AUTOSAR XML (schema 3.1.2)
standard types defined: SInt8, UInt8, UInt16, UInt32, Boolean
package /System
  ecu instance CEM: com-processing-period=0.005
    can communication controller CEMController
    communication connector ComConnector: channel=Channel, comm-controller=CEMController
  ecu instance REM: com-processing-period=0.005
    can communication controller REMController
    communication connector ComConnector: channel=Channel, comm-controller=REMController
  system TargetSystem: fibex-element=[CEM, CanCluster, IDPU_BRAKE, IDPU_BRAKE, SIG_BRAKE_IDPU_BRAKE, IPDU_LEFT_RIGHT, IPDU_LEFT_RIGHT, SIG_LEFT_IPDU_LEFT_RIGHT, SIG_RIGHT_IPDU_LEFT_RIGHT]
    mapping MAPPING
      sw-mappings:
        swc to ecu mapping a88e37d21c78744b19b30be8be6fa7d: ecu-instance=CEM
          component:
            BodyDemoArchitecture.IoHwAb_CEM.ADC2Voltage
            BodyDemoArchitecture.BrakePedalSensor
            BodyDemoArchitecture.WarnLightsSensor
            BodyDemoArchitecture.IoHwAb_CEM.IoHwAbCEMDioComponent
            BodyDemoArchitecture.Indicator.IndicatorAtomic
            BodyDemoArchitecture.PedalToLamp
            BodyDemoArchitecture.TurnSwitchSensor
            BodyDemoArchitecture.CalprmComponent
        swc to ecu mapping ab7ad628e75594871bc1c9ff9870552: ecu-instance=REM
          component:
            BodyDemoArchitecture.RearLeftActuator
            BodyDemoArchitecture.IoHwAb_REM.IoHwAbREMDioComponent
            BodyDemoArchitecture.BrakeLampActuator
            BodyDemoArchitecture.IoHwAb_REM.Percentage2DIO
            BodyDemoArchitecture.RearRightActuator
    software composition BodyDemoArchitecture: software-composition=BodyDemoArchitecture
package /System/Cluster
  can cluster CanCluster: speed=0
    physical channel Channel
      frame IDPU_BRAKE: id 0x101, from CEM, to REM, frame-length=4, can-addressing-mode=STANDARD
        carries pdu IDPU_BRAKE: packing-byte-order=big-endian, start-position=7
        pdu IDPU_BRAKE: length=32, cyclic-timing={repeating-time=0.1, starting-time=0}, minimum-delay=0.02
          signal SIG_BRAKE_IDPU_BRAKE: start 7, 32 bit, big-endian, data-type=UInt32, to REM
      frame IPDU_LEFT_RIGHT: id 0x100, from CEM, to REM, frame-length=2, can-addressing-mode=STANDARD
        carries pdu IPDU_LEFT_RIGHT: packing-byte-order=big-endian, start-position=7
        pdu IPDU_LEFT_RIGHT: length=16, cyclic-timing={repeating-time=0.1, starting-time=0}, minimum-delay=0.02
          signal SIG_LEFT_IPDU_LEFT_RIGHT: start 7, 8 bit, big-endian, data-type=SInt8, to REM
          signal SIG_RIGHT_IPDU_LEFT_RIGHT: start 15, 8 bit, big-endian, data-type=SInt8, to REM
package /Application
  composition type BodyDemoArchitecture
    11 x component:
      Indicator: type=Indicator
      IoHwAb_CEM: type=IoHwAb_CEM
      IoHwAb_REM: type=IoHwAb_REM
      TurnSwitchSensor: type=TurnSwitchSensor
      WarnLightsSensor: type=WarnLightsSensor
      RearLeftActuator: type=RearLeftActuator
      RearRightActuator: type=RearRightActuator
      BrakePedalSensor: type=BrakePedalSensor
      PedalToLamp: type=PedalToLamp
      BrakeLampActuator: type=BrakeLampActuator
      CalprmComponent: type=CalprmComponent
    connect Indicator.right -> RearRightActuator.signal
    connect Indicator.left -> RearLeftActuator.signal
    connect IoHwAb_CEM.wls -> WarnLightsSensor.io
    connect IoHwAb_REM.rightIndicatorBulb -> RearRightActuator.io
    connect IoHwAb_CEM.tss_right -> TurnSwitchSensor.right
    connect IoHwAb_REM.leftBrakeLamp -> BrakeLampActuator.io_left
    connect IoHwAb_REM.rightBrakeLamp -> BrakeLampActuator.io_right
    connect PedalToLamp.lamp -> BrakeLampActuator.signal
    connect TurnSwitchSensor.out -> Indicator.tss
    connect IoHwAb_CEM.tss_left -> TurnSwitchSensor.left
    connect WarnLightsSensor.out -> Indicator.wls
    connect IoHwAb_REM.leftIndicatorBulb -> RearLeftActuator.io
    connect BrakePedalSensor.pedal -> PedalToLamp.pedal
    connect IoHwAb_CEM.pedal -> BrakePedalSensor.io
  composition type Indicator
    require port tss: unqueued-receiver-com-spec{data-element=if_tss/value, init-value=aa75e85b0e48d493f9208f4aeb0a607, resync-time=0}, required-interface=if_tss
    require port wls: queued-receiver-com-spec{data-element=event, queue-length=1}, required-interface=if_wls
    provide port left: unqueued-sender-com-spec=LEFT, provided-interface=if_bulb_left
    provide port right: unqueued-sender-com-spec=RIGHT, provided-interface=if_bulb_right
    component IndicatorAtomic: type=IndicatorAtomic
    delegate IndicatorAtomic.wls <-> outer port Indicator/wls
    delegate IndicatorAtomic.tss <-> outer port Indicator/tss
    delegate IndicatorAtomic.left <-> outer port Indicator/left
    delegate IndicatorAtomic.right <-> outer port Indicator/right
  sender receiver interface if_tss
    data value: type=dt_tss
  integer type dt_tss: lower-limit=-128, upper-limit=127
  sender receiver interface if_wls
    data event: type=dt_wls, is-queued=true
  integer type dt_wls: lower-limit=0, upper-limit=255
  sender receiver interface if_bulb_left
    data LEFT: type=dt_bulb
  sender receiver interface if_bulb_right
    data RIGHT: type=dt_bulb
  integer type dt_bulb: lower-limit=-128, upper-limit=127
  constant specification aa75e85b0e48d493f9208f4aeb0a607
    value:
      integer literal aa75e85b0e48d493f9208f4aeb0a607: type=dt_tss, value=0
  constant specification aeba547061bbc4f628a465c655b5dce
    value:
      integer literal aeba547061bbc4f628a465c655b5dce: type=dt_bulb, value=0
  constant specification a6086f2506f88401497b997b97eebe1
    value:
      integer literal a6086f2506f88401497b997b97eebe1: type=dt_bulb, value=0
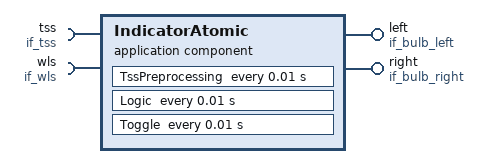
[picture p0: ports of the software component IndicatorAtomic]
  application software component type IndicatorAtomic
    require port tss: unqueued-receiver-com-spec{data-element=if_tss/value, init-value=aa75e85b0e48d493f9208f4aeb0a607, resync-time=0}, required-interface=if_tss
    require port wls: queued-receiver-com-spec{data-element=event, queue-length=1}, required-interface=if_wls
    provide port left: unqueued-sender-com-spec{data-element=LEFT, init-value=aeba547061bbc4f628a465c655b5dce}, provided-interface=if_bulb_left
    provide port right: unqueued-sender-com-spec{data-element=RIGHT, init-value=a6086f2506f88401497b997b97eebe1}, provided-interface=if_bulb_right
  internal behavior IB_IndicatorAtomic: component=IndicatorAtomic
    data received event WlsEventReceived: start-on-event=WlsPreprocessing, data=wls.event
    timing event TssCyclic10ms: start-on-event=TssPreprocessing, period=0.01
    timing event LogicCyclic10ms: start-on-event=Logic, period=0.01
    timing event ToggleCyclic10ms: start-on-event=Toggle, period=0.01
    exclusive area ea1
    exclusive area ea2
    8 x inter runnable variable:
      indicator_status: type=dt_is, communication-approach=IMPLICIT, init-value=a2aeeb626cf3e4245a92932e870d65f
      wls_status: type=dt_wls, communication-approach=IMPLICIT, init-value=a40037445f1c546d5ae7e79459c02b6
      tss_status: type=dt_tss, communication-approach=IMPLICIT, init-value=a7ba438111a914ed899a66eb1f9c4ee
      bool{0..4}: type=Boolean, communication-approach=EXPLICIT
    per-instance-calprms:
      calprm element prototype CalprmValue2: category=VALUE, sw-calibration-access=READ-WRITE, sw-record-layout=RL_UInt8, type=UInt8
    per instance memory PerInstanceMemory: type=myType, type-definition=uint32
    4 x runnable:
      TssPreprocessing: can-enter-exclusive-area=ea1, per-instance-calprm-access=IB_IndicatorAtomic/CalprmValue2, shared-calprm-access=IB_IndicatorAtomic/CalprmValue1, written-variable=[tss_status, bool0, bool1, bool2, bool3, bool4]
        data read access TssPreprocessing_DRA_1_ia: data-element=tss.value
      WlsPreprocessing: runs-inside-exclusive-area=ea2, written-variable=wls_status
        data receive point WlsPreprocessing_DRP_1_ia: data-element=wls.event
      Logic: read-variable=[tss_status, wls_status, bool0, bool1, bool2, bool3, bool4], written-variable=indicator_status
      Toggle: read-variable=indicator_status
        data write access Toggle_DWA_1_ia: data-element=left.LEFT
        data write access Toggle_DWA_2_ia: data-element=right.RIGHT
    service-needss:
      swc nv block needs SwcNvBlockNeed1: n-data-sets=1, readonly=true, reliability=HIGH, resistant-to-changed-sw=false, restore-at-start=true, write-only-once=false, writing-frequency=1, writing-priority=HIGH
      swc nv block needs SwcNvBlockNeed2: n-data-sets=1, readonly=false, reliability=LOW, resistant-to-changed-sw=false, restore-at-start=true, write-only-once=false, writing-frequency=1, writing-priority=LOW
    shared-calprms:
      calprm element prototype CalprmValue1: category=VALUE, sw-calibration-access=READ-WRITE, sw-record-layout=RL_UInt16, type=UInt16
  integer type dt_is: compu {1=LEFT_SIGNAL, 2=RIGHT_SIGNAL, 3=BOTH_SIGNAL, 0=false}, lower-limit=0, upper-limit=65535
  integer type AuxU16_dt_is: lower-limit=0, upper-limit=65535
  constant specification a2aeeb626cf3e4245a92932e870d65f
    value:
      integer literal a2aeeb626cf3e4245a92932e870d65f: type=dt_is, value=0
  constant specification a40037445f1c546d5ae7e79459c02b6
    value:
      integer literal a40037445f1c546d5ae7e79459c02b6: type=dt_wls, value=0
  constant specification a7ba438111a914ed899a66eb1f9c4ee
    value:
      integer literal a7ba438111a914ed899a66eb1f9c4ee: type=dt_tss, value=0
  swc implementation IMPL_IndicatorAtomic: behavior=IB_IndicatorAtomic
    code-descriptors:
      code IMPL_IndicatorAtomic: type=SRC
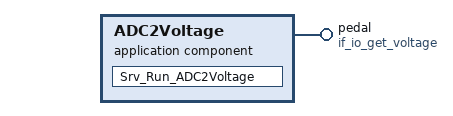
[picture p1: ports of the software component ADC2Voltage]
  application software component type ADC2Voltage
    provide port pedal: server-com-spec{operation=OP_GET, queue-length=1}, provided-interface=if_io_get_voltage
  internal behavior IB_ADC2Voltage: component=ADC2Voltage
    operation invoked event OpEv_OP_GET: start-on-event=Srv_Run_ADC2Voltage, operation=pedal.OP_GET
    runnable Srv_Run_ADC2Voltage: can-be-invoked-concurrently=true, symbol=ADC2Voltage
  swc implementation IMPL_ADC2Voltage: behavior=IB_ADC2Voltage
    code-descriptors:
      code IMPL_ADC2Voltage: type=SRC
  internal behavior IB_Percentage2DIO: component=Percentage2DIO
    4 x operation invoked event:
      OpEv_Left_OP_SET: start-on-event=Srv_Run_Left_OP_SET, operation=left.OP_SET
      OpEv_Left_OP_DIAG: start-on-event=Srv_Run_Left_OP_DIAG, operation=left.OP_DIAG
      OpEv_Right_OP_SET: start-on-event=Srv_Run_Right_OP_SET, operation=right.OP_SET
      OpEv_Right_OP_DIAG: start-on-event=Srv_Run_Right_OP_DIAG, operation=right.OP_DIAG
    4 x runnable, all with can-be-invoked-concurrently=true:
      Srv_Run_Left_OP_SET: symbol=Percentage2DIO_Left_OP_SET
        4 x sync call, all with timeout=0:
          leftNormal_OP_WC: operation=leftNormal.OP_WC
          leftFull_OP_WC: operation=leftFull.OP_WC
          leftNormal_OP_RC: operation=leftNormal.OP_RC
          leftFull_OP_RC: operation=leftFull.OP_RC
      Srv_Run_Right_OP_SET: symbol=Percentage2DIO_Right_OP_SET
        4 x sync call, all with timeout=0:
          rightFull_OP_WC: operation=rightFull.OP_WC
          rightNormal_OP_WC: operation=rightNormal.OP_WC
          rightFull_OP_RC: operation=rightFull.OP_RC
          rightNormal_OP_RC: operation=rightNormal.OP_RC
      Srv_Run_Left_OP_DIAG: symbol=Percentage2DIO_Left_OP_DIAG
      Srv_Run_Right_OP_DIAG: symbol=Percentage2DIO_Right_OP_DIAG
  swc implementation IMPL_Percentage2DIO: behavior=IB_Percentage2DIO
    code-descriptors:
      code IMPL_Percentage2DIO: type=SRC
  constant specification a51067134f9f24a9d9f2ec09784b782
    value:
      integer literal a51067134f9f24a9d9f2ec09784b782: type=dt_tss, value=0
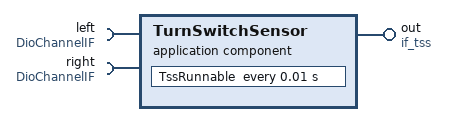
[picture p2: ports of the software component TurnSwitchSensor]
  application software component type TurnSwitchSensor
    provide port out: unqueued-sender-com-spec{data-element=if_tss/value, init-value=a51067134f9f24a9d9f2ec09784b782}, provided-interface=if_tss
    require port left: required-interface=DioChannelIF
    require port right: required-interface=DioChannelIF
  internal behavior IB_TurnSwitchSensor: component=TurnSwitchSensor
    timing event TimingEvent_10ms: start-on-event=TssRunnable, period=0.01
    runnable TssRunnable
      data write access DWA_out_value: data-element=out.value
      4 x sync call, all with timeout=0:
        left_OP_RC: operation=left.OP_RC
        left_OP_WC: operation=left.OP_WC
        right_OP_WC: operation=right.OP_WC
        right_OP_RC: operation=right.OP_RC
  swc implementation IMPL_TurnSwitchSensor: behavior=IB_TurnSwitchSensor
    code-descriptors:
      code IMPL_TurnSwitchSensor: type=SRC
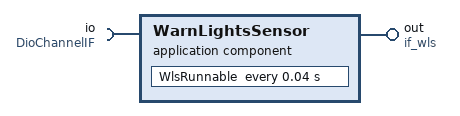
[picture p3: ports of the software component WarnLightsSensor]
  application software component type WarnLightsSensor
    provide port out: queued-sender-com-spec=event, provided-interface=if_wls
    require port io: required-interface=DioChannelIF
  internal behavior IB_WarnLightsSensor: component=WarnLightsSensor
    timing event TimingEvent_40ms: start-on-event=WlsRunnable, period=0.04
    runnable WlsRunnable
      data send point DSP_out_event: data-element=out.event
      sync call io_OP_RC: operation=io.OP_RC, timeout=0
      sync call io_OP_WC: operation=io.OP_WC, timeout=0
  swc implementation IMPL_WarnLightsSensor: behavior=IB_WarnLightsSensor
    code-descriptors:
      code IMPL_WarnLightsSensor: type=SRC
  constant specification a54a6a9694b41497d943bf20cd91112
    value:
      integer literal a54a6a9694b41497d943bf20cd91112: type=dt_bulb, value=0
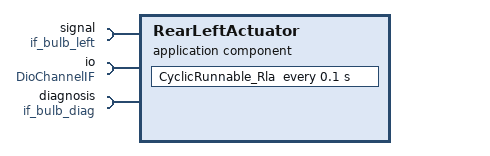
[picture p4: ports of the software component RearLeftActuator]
  application software component type RearLeftActuator
    require port signal: unqueued-receiver-com-spec{data-element=LEFT, init-value=a54a6a9694b41497d943bf20cd91112, resync-time=0}, required-interface=if_bulb_left
    require port io: required-interface=DioChannelIF
    require port diagnosis: required-interface=if_bulb_diag
  client server interface if_bulb_diag
    operation SetStatus
      arg status: type=dt_diag_status, direction=IN
  integer type dt_diag_status: compu {0=no_problem, 1=problem}, lower-limit=0, upper-limit=65535
  integer type AuxU16_dt_diag_status: lower-limit=0, upper-limit=65535
  internal behavior IB_RearLeftActuator: component=RearLeftActuator
    timing event Cyclic100ms: start-on-event=CyclicRunnable_Rla, period=0.1
    runnable CyclicRunnable_Rla
      data read access DRA_signal_value: data-element=signal.LEFT
      sync call diagnosis_SetStatus: operation=diagnosis.SetStatus, timeout=0
      sync call io_OP_WC: operation=io.OP_WC, timeout=0
      sync call io_OP_RC: operation=io.OP_RC, timeout=0
  swc implementation IMPL_FrontLeftActuator: behavior=IB_RearLeftActuator
    code-descriptors:
      code IMPL_FrontLeftActuator: type=SRC
  constant specification aead801ed2e734a3aa2dc432880381f
    value:
      integer literal aead801ed2e734a3aa2dc432880381f: type=dt_bulb, value=0
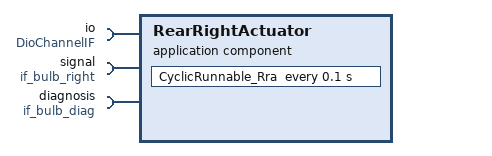
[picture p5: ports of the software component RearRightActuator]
  application software component type RearRightActuator
    require port io: required-interface=DioChannelIF
    require port signal: unqueued-receiver-com-spec{data-element=RIGHT, init-value=aead801ed2e734a3aa2dc432880381f, resync-time=0}, required-interface=if_bulb_right
    require port diagnosis: required-interface=if_bulb_diag
  internal behavior IB_RearRightActuator: component=RearRightActuator
    timing event Cyclic100ms: start-on-event=CyclicRunnable_Rra, period=0.1
    runnable CyclicRunnable_Rra
      data read access DRA_signal_value: data-element=signal.RIGHT
      sync call diagnosis_SetStatus: operation=diagnosis.SetStatus, timeout=0
      sync call io_OP_WC: operation=io.OP_WC, timeout=0
      sync call io_OP_RC: operation=io.OP_RC, timeout=0
  swc implementation IMPL_FrontRightActuator: behavior=IB_RearRightActuator
    code-descriptors:
      code IMPL_FrontRightActuator: type=SRC
  constant specification af237034bf74f4bf5920f44a10a4f76
    value:
      integer literal af237034bf74f4bf5920f44a10a4f76: type=dt_percentage, value=0
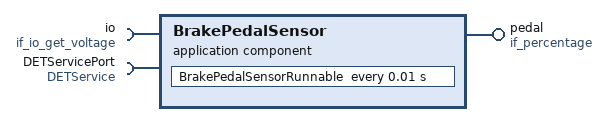
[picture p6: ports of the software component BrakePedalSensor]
  application software component type BrakePedalSensor
    provide port pedal: unqueued-sender-com-spec{data-element=if_percentage/value, init-value=af237034bf74f4bf5920f44a10a4f76}, provided-interface=if_percentage
    require port io: required-interface=if_io_get_voltage
    require port DETServicePort: required-interface=DETService
  sender receiver interface if_percentage
    data value: type=dt_percentage
  sender receiver interface if_brake
    data BRAKE: type=dt_percentage
  integer type dt_percentage: compu {}, lower-limit=0, upper-limit=4294967295
  integer type AuxU32_dt_percentage: lower-limit=0, upper-limit=4294967295
  internal behavior IB_BrakePedalSensor: component=BrakePedalSensor
    timing event Timing_10ms: start-on-event=BrakePedalSensorRunnable, period=0.01
    runnable BrakePedalSensorRunnable
      data write access DWA_pedal_value: data-element=pedal.value
      sync call io_OP_GET: operation=io.OP_GET, timeout=0
      sync call DETServicePort_ReportError: operation=DETServicePort.ReportError, timeout=0
  swc implementation IMPL_BrakePedalSensor: behavior=IB_BrakePedalSensor
    code-descriptors:
      code IMPL_BrakePedalSensor: type=SRC
  constant specification af536b2f1f3374592a77e6ba25805e6
    value:
      integer literal af536b2f1f3374592a77e6ba25805e6: type=dt_percentage, value=0
  constant specification a34ded2542c4b4ab7930b8ab2fa0993
    value:
      integer literal a34ded2542c4b4ab7930b8ab2fa0993: type=dt_percentage, value=0
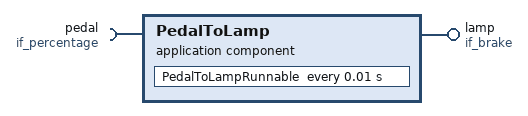
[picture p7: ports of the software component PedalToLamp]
  application software component type PedalToLamp
    require port pedal: unqueued-receiver-com-spec{data-element=if_percentage/value, init-value=af536b2f1f3374592a77e6ba25805e6, resync-time=0}, required-interface=if_percentage
    provide port lamp: unqueued-sender-com-spec{data-element=BRAKE, init-value=a34ded2542c4b4ab7930b8ab2fa0993}, provided-interface=if_brake
  internal behavior IB_PedalToLamp: component=PedalToLamp
    timing event Timing_10ms: start-on-event=PedalToLampRunnable, period=0.01
    runnable PedalToLampRunnable
      data read access DRA_pedal_value: data-element=pedal.value
      data write access DWA_lamp_value: data-element=lamp.BRAKE
  swc implementation IMPL_PedalToLamp: behavior=IB_PedalToLamp
    code-descriptors:
      code IMPL_PedalToLamp: type=SRC
  constant specification a674ab0de6f3d43caacb785465b088c
    value:
      integer literal a674ab0de6f3d43caacb785465b088c: type=dt_percentage, value=0
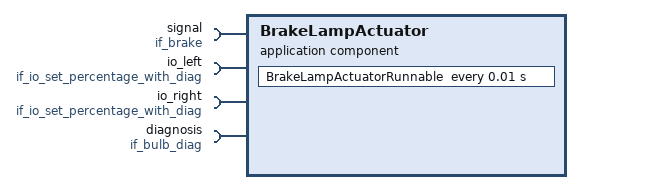
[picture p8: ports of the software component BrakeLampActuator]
  application software component type BrakeLampActuator
    4 x require port:
      signal: unqueued-receiver-com-spec{data-element=BRAKE, init-value=a674ab0de6f3d43caacb785465b088c, resync-time=0}, required-interface=if_brake
      io_left: required-interface=if_io_set_percentage_with_diag
      io_right: required-interface=if_io_set_percentage_with_diag
      diagnosis: required-interface=if_bulb_diag
  internal behavior IB_BrakeLampActuator: component=BrakeLampActuator
    timing event Timing_10ms: start-on-event=BrakeLampActuatorRunnable, period=0.01
    runnable BrakeLampActuatorRunnable
      data read access DRA_signal_value: data-element=signal.BRAKE
      5 x sync call, all with timeout=0:
        io_left_OP_SET: operation=io_left.OP_SET
        io_left_OP_DIAG: operation=io_left.OP_DIAG
        io_right_OP_SET: operation=io_right.OP_SET
        io_right_OP_DIAG: operation=io_right.OP_DIAG
        diagnosis_SetStatus: operation=diagnosis.SetStatus
  swc implementation IMPL_BrakeLampActuator: behavior=IB_BrakeLampActuator
    code-descriptors:
      code IMPL_BrakeLampActuator: type=SRC
  constant specification a44a60d3d162743dbae6e6dbb052677
    value:
      integer literal a44a60d3d162743dbae6e6dbb052677: type=dt_diag_status, value=0
  sender receiver interface if_diag_status
    data status: type=dt_diag_status
package /IoHwAbsPackage
  composition type IoHwAb_CEM
    4 x provide port:
      tss_left: provided-com-specs=[{operation=OP_WC, queue-length=1}, {operation=OP_RC, queue-length=1}], provided-interface=DioChannelIF
      tss_right: provided-com-specs=[{operation=OP_WC, queue-length=1}, {operation=OP_RC, queue-length=1}], provided-interface=DioChannelIF
      wls: provided-com-specs=[{operation=OP_WC, queue-length=1}, {operation=OP_RC, queue-length=1}], provided-interface=DioChannelIF
      pedal: server-com-spec{operation=OP_GET, queue-length=1}, provided-interface=if_io_get_voltage
    component ADC2Voltage: type=ADC2Voltage
    component IoHwAbCEMDioComponent: type=IoHwAbCEMDioComponent
    delegate ADC2Voltage.pedal <-> outer port IoHwAb_CEM/pedal
    delegate IoHwAbCEMDioComponent.S2_WARNLIGHT_SWITCH <-> outer port wls
    delegate IoHwAbCEMDioComponent.S1_TURN_SWITCH_RIGHT <-> outer port tss_right
    delegate IoHwAbCEMDioComponent.S4_TURN_SWITCH_LEFT <-> outer port tss_left
  composition type IoHwAb_REM
    4 x provide port:
      leftIndicatorBulb: provided-com-specs=[{operation=OP_WC, queue-length=1}, {operation=OP_RC, queue-length=1}], provided-interface=DioChannelIF
      rightIndicatorBulb: provided-com-specs=[{operation=OP_WC, queue-length=1}, {operation=OP_RC, queue-length=1}], provided-interface=DioChannelIF
      leftBrakeLamp: provided-com-specs=[{operation=OP_DIAG, queue-length=1}, {operation=OP_SET, queue-length=1}], provided-interface=if_io_set_percentage_with_diag
      rightBrakeLamp: provided-com-specs=[{operation=OP_DIAG, queue-length=1}, {operation=OP_SET, queue-length=1}], provided-interface=if_io_set_percentage_with_diag
    component Percentage2DIO: type=Percentage2DIO
    component IoHwAbREMDioComponent: type=IoHwAbREMDioComponent
    delegate IoHwAbREMDioComponent.LED8_INDICATOR_LEFT <-> outer port leftIndicatorBulb
    delegate IoHwAbREMDioComponent.LED1_INDICATOR_RIGHT <-> outer port rightIndicatorBulb
    delegate Percentage2DIO.right <-> outer port rightBrakeLamp
    delegate Percentage2DIO.left <-> outer port leftBrakeLamp
    connect IoHwAbREMDioComponent.LED7_BRAKELIGHT_NORMAL_LEFT -> Percentage2DIO.leftNormal
    connect IoHwAbREMDioComponent.LED3_BRAKELIGHT_FULL_RIGHT -> Percentage2DIO.rightFull
    connect IoHwAbREMDioComponent.LED2_BRAKELIGHT_NORMAL_RIGHT -> Percentage2DIO.rightNormal
    connect IoHwAbREMDioComponent.LED6_BRAKELIGHT_FULL_LEFT -> Percentage2DIO.leftFull
  integer type IoHwAb_UInt16: lower-limit=0, upper-limit=65535
  integer type IoHwAb_UInt8: lower-limit=0, upper-limit=255
  integer type IoHwAb_UInt32: lower-limit=0, upper-limit=4294967295
package /IoHwAbsPackage/DioPackage
  4 x integer type, all with lower-limit=0:
    IoHwAb_LT: upper-limit=1
    IoHwAb_Dio_PortType: upper-limit=4294967295
    IoHwAb_Dio_PortLevelType: upper-limit=65535
    IoHwAb_Dio_ChannelType: upper-limit=4294967295
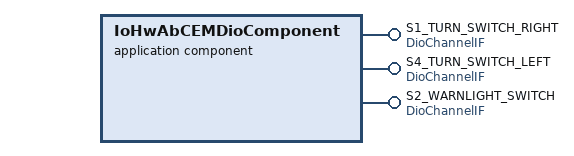
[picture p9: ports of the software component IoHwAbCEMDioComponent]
  application software component type IoHwAbCEMDioComponent
    provide port S1_TURN_SWITCH_RIGHT: provided-com-specs=[{operation=OP_RC, queue-length=1}, {operation=OP_WC, queue-length=1}], provided-interface=DioChannelIF
    provide port S4_TURN_SWITCH_LEFT: provided-com-specs=[{operation=OP_RC, queue-length=1}, {operation=OP_WC, queue-length=1}], provided-interface=DioChannelIF
    provide port S2_WARNLIGHT_SWITCH: provided-com-specs=[{operation=OP_RC, queue-length=1}, {operation=OP_WC, queue-length=1}], provided-interface=DioChannelIF
  client server interface DioChannelIF
    operation OP_RC
      arg IoHwAbReturned: type=IoHwAb_LT, direction=OUT
    operation OP_WC
      arg Level: type=IoHwAb_LT, direction=IN
  client server interface DioPortIF
    4 x operation:
      OP_WCG
        arg Offset: type=IoHwAb_UInt8, direction=IN
        arg Mask: type=IoHwAb_Dio_PortLevelType, direction=IN
        arg Level: type=IoHwAb_Dio_PortLevelType, direction=IN
      OP_WP
        arg Level: type=IoHwAb_Dio_PortLevelType, direction=IN
      OP_RCG
        arg Offset: type=IoHwAb_UInt8, direction=IN
        arg Mask: type=IoHwAb_Dio_PortLevelType, direction=IN
        arg IoHwAbReturned: type=IoHwAb_Dio_PortLevelType, direction=OUT
      OP_RP
        arg IoHwAbReturned: type=IoHwAb_Dio_PortLevelType, direction=OUT
  internal behavior IoHwAbsCEMDioIB: component=IoHwAbCEMDioComponent
    6 x operation invoked event:
      S1_TURN_SWITCH_RIGHT_RC: start-on-event=IoHwAbsCEMDioIB/RC_RUN, operation=S1_TURN_SWITCH_RIGHT.OP_RC
      S1_TURN_SWITCH_RIGHT_WC: start-on-event=IoHwAbsCEMDioIB/WC_RUN, operation=S1_TURN_SWITCH_RIGHT.OP_WC
      S4_TURN_SWITCH_LEFT_RC: start-on-event=IoHwAbsCEMDioIB/RC_RUN, operation=S4_TURN_SWITCH_LEFT.OP_RC
      S4_TURN_SWITCH_LEFT_WC: start-on-event=IoHwAbsCEMDioIB/WC_RUN, operation=S4_TURN_SWITCH_LEFT.OP_WC
      S2_WARNLIGHT_SWITCH_RC: start-on-event=IoHwAbsCEMDioIB/RC_RUN, operation=S2_WARNLIGHT_SWITCH.OP_RC
      S2_WARNLIGHT_SWITCH_WC: start-on-event=IoHwAbsCEMDioIB/WC_RUN, operation=S2_WARNLIGHT_SWITCH.OP_WC
    port-api-option indirect-api=false, port=S1_TURN_SWITCH_RIGHT:
      port-arg-values:
        integer literal intLit9: type=IoHwAb_Dio_ChannelType, value=8
    port-api-option indirect-api=false, port=S4_TURN_SWITCH_LEFT:
      port-arg-values:
        integer literal intLit10: type=IoHwAb_Dio_ChannelType, value=9
    port-api-option indirect-api=false, port=S2_WARNLIGHT_SWITCH:
      port-arg-values:
        integer literal intLit11: type=IoHwAb_Dio_ChannelType, value=10
    6 x runnable, all with can-be-invoked-concurrently=true:
      RC_RUN: symbol=IoHwAb_Dio_ReadChannel
      WCG_RUN: symbol=IoHwAb_Dio_WriteChannelGroup
      WP_RUN: symbol=IoHwAb_Dio_WritePort
      WC_RUN: symbol=IoHwAb_Dio_WriteChannel
      RCG_RUN: symbol=IoHwAb_Dio_ReadChannelGroup
      RP_RUN: symbol=IoHwAb_Dio_ReadPort
  swc implementation IoHwAbsCEMDioIMPL: behavior=IoHwAbsCEMDioIB
    code-descriptors:
      code IoHwAbsDioCode: type=SRC
  application software component type IoHwAbREMDioComponent
    9 x provide port:
      LED1_INDICATOR_RIGHT: provided-com-specs=[{operation=OP_WC, queue-length=1}, {operation=OP_RC, queue-length=1}], provided-interface=DioChannelIF
      LED2_BRAKELIGHT_NORMAL_RIGHT: provided-com-specs=[{operation=OP_WC, queue-length=1}, {operation=OP_RC, queue-length=1}], provided-interface=DioChannelIF
      LED3_BRAKELIGHT_FULL_RIGHT: provided-com-specs=[{operation=OP_WC, queue-length=1}, {operation=OP_RC, queue-length=1}], provided-interface=DioChannelIF
      LED4_NOT_USED: provided-com-specs=[{operation=OP_WC, queue-length=1}, {operation=OP_RC, queue-length=1}], provided-interface=DioChannelIF
      LED5_NOT_USED: provided-com-specs=[{operation=OP_WC, queue-length=1}, {operation=OP_RC, queue-length=1}], provided-interface=DioChannelIF
      LED6_BRAKELIGHT_FULL_LEFT: provided-com-specs=[{operation=OP_WC, queue-length=1}, {operation=OP_RC, queue-length=1}], provided-interface=DioChannelIF
      LED7_BRAKELIGHT_NORMAL_LEFT: provided-com-specs=[{operation=OP_WC, queue-length=1}, {operation=OP_RC, queue-length=1}], provided-interface=DioChannelIF
      LED8_INDICATOR_LEFT: provided-com-specs=[{operation=OP_WC, queue-length=1}, {operation=OP_RC, queue-length=1}], provided-interface=DioChannelIF
      INDICATOR_CTRL_PORT: provided-interface=DioPortIF
        provided-com-specs:
          operation=OP_RP, queue-length=1
          operation=OP_RCG, queue-length=1
          operation=OP_WP, queue-length=1
          operation=OP_WCG, queue-length=1
  internal behavior IoHwAbsREMDioIB: component=IoHwAbREMDioComponent
    20 x operation invoked event:
      LED1_INDICATOR_RIGHT_RC: start-on-event=IoHwAbsREMDioIB/RC_RUN, operation=LED1_INDICATOR_RIGHT.OP_RC
      LED1_INDICATOR_RIGHT_WC: start-on-event=IoHwAbsREMDioIB/WC_RUN, operation=LED1_INDICATOR_RIGHT.OP_WC
      LED2_BRAKELIGHT_NORMAL_RIGHT_RC: start-on-event=IoHwAbsREMDioIB/RC_RUN, operation=LED2_BRAKELIGHT_NORMAL_RIGHT.OP_RC
      LED2_BRAKELIGHT_NORMAL_RIGHT_WC: start-on-event=IoHwAbsREMDioIB/WC_RUN, operation=LED2_BRAKELIGHT_NORMAL_RIGHT.OP_WC
      LED3_BRAKELIGHT_FULL_RIGHT_RC: start-on-event=IoHwAbsREMDioIB/RC_RUN, operation=LED3_BRAKELIGHT_FULL_RIGHT.OP_RC
      LED3_BRAKELIGHT_FULL_RIGHT_WC: start-on-event=IoHwAbsREMDioIB/WC_RUN, operation=LED3_BRAKELIGHT_FULL_RIGHT.OP_WC
      LED4_NOT_USED_RC: start-on-event=IoHwAbsREMDioIB/RC_RUN, operation=LED4_NOT_USED.OP_RC
      LED4_NOT_USED_WC: start-on-event=IoHwAbsREMDioIB/WC_RUN, operation=LED4_NOT_USED.OP_WC
      LED5_NOT_USED_RC: start-on-event=IoHwAbsREMDioIB/RC_RUN, operation=LED5_NOT_USED.OP_RC
      LED5_NOT_USED_WC: start-on-event=IoHwAbsREMDioIB/WC_RUN, operation=LED5_NOT_USED.OP_WC
      LED6_BRAKELIGHT_FULL_LEFT_RC: start-on-event=IoHwAbsREMDioIB/RC_RUN, operation=LED6_BRAKELIGHT_FULL_LEFT.OP_RC
      LED6_BRAKELIGHT_FULL_LEFT_WC: start-on-event=IoHwAbsREMDioIB/WC_RUN, operation=LED6_BRAKELIGHT_FULL_LEFT.OP_WC
      LED7_BRAKELIGHT_NORMAL_LEFT_RC: start-on-event=IoHwAbsREMDioIB/RC_RUN, operation=LED7_BRAKELIGHT_NORMAL_LEFT.OP_RC
      LED7_BRAKELIGHT_NORMAL_LEFT_WC: start-on-event=IoHwAbsREMDioIB/WC_RUN, operation=LED7_BRAKELIGHT_NORMAL_LEFT.OP_WC
      LED8_INDICATOR_LEFT_RC: start-on-event=IoHwAbsREMDioIB/RC_RUN, operation=LED8_INDICATOR_LEFT.OP_RC
      LED8_INDICATOR_LEFT_WC: start-on-event=IoHwAbsREMDioIB/WC_RUN, operation=LED8_INDICATOR_LEFT.OP_WC
      INDICATOR_CTRL_PORT_WCG: start-on-event=IoHwAbsREMDioIB/WCG_RUN, operation=INDICATOR_CTRL_PORT.OP_WCG
      INDICATOR_CTRL_PORT_WP: start-on-event=IoHwAbsREMDioIB/WP_RUN, operation=INDICATOR_CTRL_PORT.OP_WP
      INDICATOR_CTRL_PORT_RCG: start-on-event=IoHwAbsREMDioIB/RCG_RUN, operation=INDICATOR_CTRL_PORT.OP_RCG
      INDICATOR_CTRL_PORT_RP: start-on-event=IoHwAbsREMDioIB/RP_RUN, operation=INDICATOR_CTRL_PORT.OP_RP
    port-api-option indirect-api=false, port=LED1_INDICATOR_RIGHT:
      port-arg-values:
        integer literal PA_WC_RUN1: type=UInt32, value=0
    port-api-option indirect-api=false, port=LED2_BRAKELIGHT_NORMAL_RIGHT:
      port-arg-values:
        integer literal PA_WC_RUN2: type=UInt32, value=1
    port-api-option indirect-api=false, port=LED3_BRAKELIGHT_FULL_RIGHT:
      port-arg-values:
        integer literal PA_WC_RUN3: type=UInt32, value=2
    port-api-option indirect-api=false, port=LED4_NOT_USED:
      port-arg-values:
        integer literal PA_WC_RUN4: type=UInt32, value=3
    port-api-option indirect-api=false, port=LED5_NOT_USED:
      port-arg-values:
        integer literal PA_WC_RUN5: type=UInt32, value=4
    port-api-option indirect-api=false, port=LED6_BRAKELIGHT_FULL_LEFT:
      port-arg-values:
        integer literal PA_WC_RUN6: type=UInt32, value=5
    port-api-option indirect-api=false, port=LED7_BRAKELIGHT_NORMAL_LEFT:
      port-arg-values:
        integer literal PA_RC_RUN7: type=UInt32, value=6
    port-api-option indirect-api=false, port=LED8_INDICATOR_LEFT:
      port-arg-values:
        integer literal PA_WC_RUN8: type=UInt32, value=7
    port-api-option indirect-api=false, port=INDICATOR_CTRL_PORT:
      port-arg-values:
        integer literal PA_RP_RUN1: type=UInt8, value=0
    6 x runnable, all with can-be-invoked-concurrently=true:
      RC_RUN: symbol=IoHwAb_Dio_ReadChannel
      WCG_RUN: symbol=IoHwAb_Dio_WriteChannelGroup
      WP_RUN: symbol=IoHwAb_Dio_WritePort
      WC_RUN: symbol=IoHwAb_Dio_WriteChannel
      RCG_RUN: symbol=IoHwAb_Dio_ReadChannelGroup
      RP_RUN: symbol=IoHwAb_Dio_ReadPort
  swc implementation IoHwAbsREMDioIMPL: behavior=IoHwAbsREMDioIB
    code-descriptors:
      code IoHwAbsREMDioIMPL: type=SRC
package /Services
  client server interface if_io_get_voltage
    operation OP_GET
      arg value: type=IoHwAb_VoltageType, direction=OUT
  integer type ModuleIdType: lower-limit=0, upper-limit=65535
  client server interface DETService: is-service=true
    operation ReportError
      arg InstanceId: type=UInt8, direction=IN
      arg ApiId: type=UInt8, direction=IN
      arg ErrorId: type=UInt8, direction=IN
  integer type IoHwAb_VoltageType: compu {}, lower-limit=-2147483648, upper-limit=2147483647
  integer type AuxS32_IoHwAb_VoltageType: lower-limit=-2147483648, upper-limit=2147483647
  client server interface if_io_set_percentage_with_diag
    operation OP_SET
      arg value: type=IoHwAb_PercentageType, direction=IN
    operation OP_DIAG
      arg Diagnosis: type=IoHwAb_SignalDiagnosisType, direction=OUT
  integer type IoHwAb_PercentageType: compu {}, lower-limit=0, upper-limit=4294967295
  integer type AuxU32_IoHwAb_PercentageType: lower-limit=0, upper-limit=4294967295
  integer type IoHwAb_SignalDiagnosisType: lower-limit=0, upper-limit=255
package /BodyDemo
  application software component type Percentage2DIO
    provide port left: provided-com-specs=[{operation=OP_DIAG, queue-length=1}, {operation=OP_SET, queue-length=1}], provided-interface=if_io_set_percentage_with_diag
    provide port right: provided-com-specs=[{operation=OP_DIAG, queue-length=1}, {operation=OP_SET, queue-length=1}], provided-interface=if_io_set_percentage_with_diag
    4 x require port, all with required-interface=DioChannelIF:
      leftNormal
      leftFull
      rightNormal
      rightFull
package /Default
  calprm component type CalprmComponent
    provide port Port: provided-interface=Interface
  calprm interface Interface
    calprm element prototype CalprmValue2: category=VALUE, sw-calibration-access=READ-WRITE, sw-record-layout=RL_UInt8, type=UInt8
    calprm element prototype CalprmValue1: category=VALUE, sw-calibration-access=READ-WRITE, sw-record-layout=RL_UInt32, type=UInt32
package /RecordLayouts
  sw record layout RL_UInt16
  sw record layout RL_UInt32
  sw record layout RL_UInt8
